# USB0_VBP2AHB_WRAP_CONTROLLER_VBP_USB3_CORE_EXTCAP register map
Vendor: Texas Instruments
Peripheral module from a debugger description file (folder am62P).
Registers are 32-bit, access per field, reset 0x401 unless marked. A register's access mark holds for its fields unless they carry their own. Offsets are as the file gives them; lines under a group give offsets from that group; [hi:lo] are bit positions; {n}, {i} and the like mark numbered series; 'fields as' and 'values as' point back to an identical list; <NAME> marks a mode.

## USB0_VBP2AHB_WRAP_CONTROLLER_VBP_USB3_CORE_EXTCAP
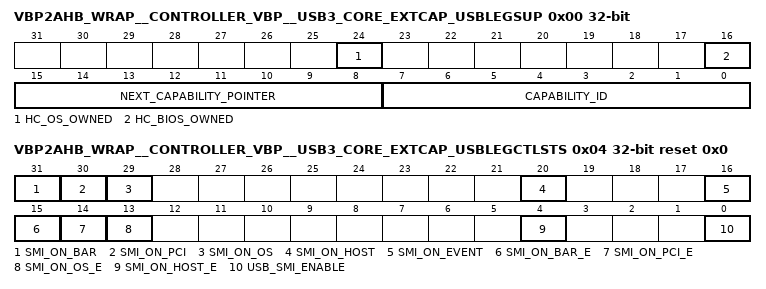
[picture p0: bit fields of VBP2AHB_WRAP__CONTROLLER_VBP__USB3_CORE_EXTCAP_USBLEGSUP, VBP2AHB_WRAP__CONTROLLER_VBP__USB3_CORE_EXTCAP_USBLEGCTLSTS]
0x00 VBP2AHB_WRAP__CONTROLLER_VBP__USB3_CORE_EXTCAP_USBLEGSUP — USBLEGSUP
  [24] HC_OS_OWNED rw — HC_OS_OWNED SEMAPHORE For a description of this standard USB register field, see the eXtensible Host Controller Interface for Universal Serial Bus [USB] Specification 3.0.
  [16] HC_BIOS_OWNED rw — HC_BIOS_OWNED SEMAPHORE For a description of this standard USB register field, see the eXtensible Host Controller Interface for Universal Serial Bus [USB] Specification 3.0.
  [15:8] NEXT_CAPABILITY_POINTER ro — NEXT_CAPABILITY_POINTER For a description of this standard USB register field, see the eXtensible Host Controller Interface for Universal Serial Bus [USB] Specification 3.0.
  [7:0] CAPABILITY_ID ro — CAPABILITY_ID set_register_field_attribute DWC_usb3_map/DWC_usb3_block_HC_Extended_Capability_Register/USBLEGSUP/CAPABILITY_ID RegisterResetValue 0x1 For a description of this standard USB register field, see the eXtensible Host Controller Interface for Universal Serial Bus [USB] Specification 3.0.
0x04 VBP2AHB_WRAP__CONTROLLER_VBP__USB3_CORE_EXTCAP_USBLEGCTLSTS access not given reset 0x0 — USBLEGCTLSTS
  [31] SMI_ON_BAR — SMI_ON_BAR For a description of this standard USB register field, see the eXtensible Host Controller Interface for Universal Serial Bus [USB] Specification 3.0. (access R/W1TC)
  [30] SMI_ON_PCI — SMI_ON_PCI COMMAND For a description of this standard USB register field, see the eXtensible Host Controller Interface for Universal Serial Bus [USB] Specification 3.0. (access R/W1TC)
  [29] SMI_ON_OS — SMI_ON_OS OWNERSHIP CHANGE For a description of this standard USB register field, see the eXtensible Host Controller Interface for Universal Serial Bus [USB] Specification 3.0. (access R/W1TC)
  [20] SMI_ON_HOST ro — SMI_ON_HOST SYSTEM ERROR For a description of this standard USB register field, see the eXtensible Host Controller Interface for Universal Serial Bus [USB] Specification 3.0.
  [16] SMI_ON_EVENT ro — SMI_ON_EVENT INTERRUPT For a description of this standard USB register field, see the eXtensible Host Controller Interface for Universal Serial Bus [USB] Specification 3.0.
  [15] SMI_ON_BAR_E rw — SMI_ON_BAR ENABLE For a description of this standard USB register field, see the eXtensible Host Controller Interface for Universal Serial Bus [USB] Specification 3.0.
  [14] SMI_ON_PCI_E rw — SMI_ON_PCI COMMAND ENABLE For a description of this standard USB register field, see the eXtensible Host Controller Interface for Universal Serial Bus [USB] Specification 3.0.
  [13] SMI_ON_OS_E rw — SMI_ON_OS OWNERSHIP ENABLE For a description of this standard USB register field, see the eXtensible Host Controller Interface for Universal Serial Bus [USB] Specification 3.0.
  [4] SMI_ON_HOST_E rw — SMI_ON_HOST SYSTEM ERROR ENABLE For a description of this standard USB register field, see the eXtensible Host Controller Interface for Universal Serial Bus [USB] Specification 3.0.
  [0] USB_SMI_ENABLE rw — USB_SMI_ENABLE For a description of this standard USB register field, see the eXtensible Host Controller Interface for Universal Serial Bus [USB] Specification 3.0.
